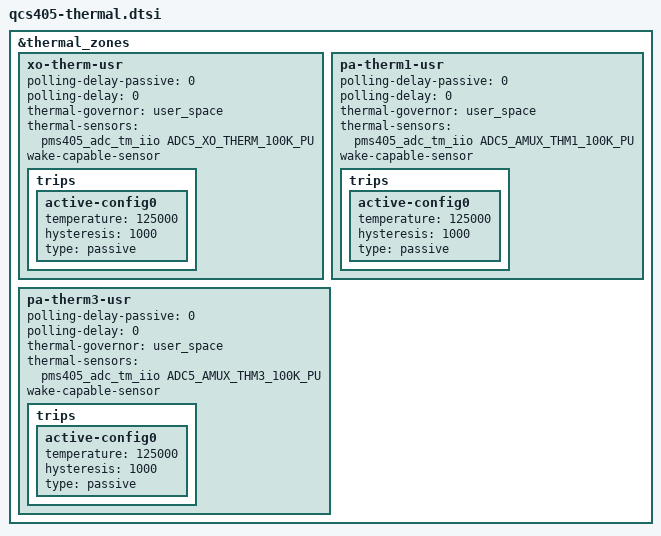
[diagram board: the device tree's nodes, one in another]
#include <dt-bindings/iio/qcom,spmi-vadc.h>

&thermal_zones {
	xo-therm-usr {
		polling-delay-passive = <0>;
		polling-delay = <0>;
		thermal-governor = "user_space";
		thermal-sensors = <&pms405_adc_tm_iio ADC5_XO_THERM_100K_PU>;
		wake-capable-sensor;

		trips {
			active-config0 {
				temperature = <125000>;
				hysteresis = <1000>;
				type = "passive";
			};
		};
	};

	pa-therm1-usr {
		polling-delay-passive = <0>;
		polling-delay = <0>;
		thermal-governor = "user_space";
		thermal-sensors = <&pms405_adc_tm_iio ADC5_AMUX_THM1_100K_PU>;
		wake-capable-sensor;

		trips {
			active-config0 {
				temperature = <125000>;
				hysteresis = <1000>;
				type = "passive";
			};
		};
	};

	pa-therm3-usr {
		polling-delay-passive = <0>;
		polling-delay = <0>;
		thermal-governor = "user_space";
		thermal-sensors = <&pms405_adc_tm_iio ADC5_AMUX_THM3_100K_PU>;
		wake-capable-sensor;

		trips {
			active-config0 {
				temperature = <125000>;
				hysteresis = <1000>;
				type = "passive";
			};
		};
	};
};
